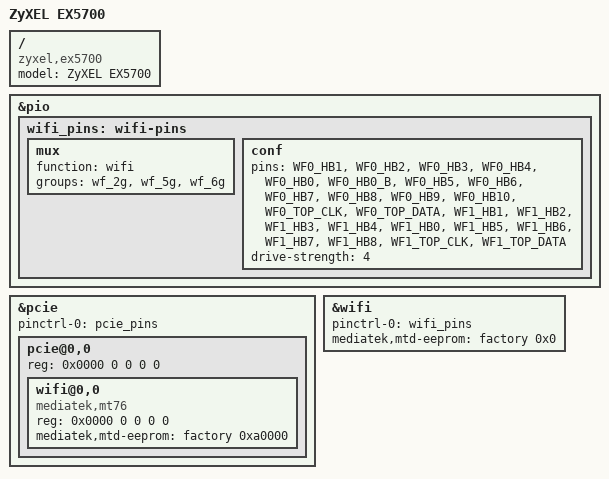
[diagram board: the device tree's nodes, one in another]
// SPDX-License-Identifier: (GPL-2.0 OR MIT)

/dts-v1/;

#include "mt7986a-zyxel-ex5700-common.dtsi"

/ {
	model = "ZyXEL EX5700";
	compatible = "zyxel,ex5700", "mediatek,mt7986a";
};

&pio {
	wifi_pins: wifi-pins {
		mux {
			function = "wifi";
			groups = "wf_2g", "wf_5g", "wf_6g";
		};
		conf {
			pins = "WF0_HB1", "WF0_HB2", "WF0_HB3", "WF0_HB4",
			       "WF0_HB0", "WF0_HB0_B", "WF0_HB5", "WF0_HB6",
			       "WF0_HB7", "WF0_HB8", "WF0_HB9", "WF0_HB10",
			       "WF0_TOP_CLK", "WF0_TOP_DATA", "WF1_HB1",
			       "WF1_HB2", "WF1_HB3", "WF1_HB4", "WF1_HB0",
			       "WF1_HB5", "WF1_HB6", "WF1_HB7", "WF1_HB8",
			       "WF1_TOP_CLK", "WF1_TOP_DATA";
			drive-strength = <4>;
		};
	};

};

&pcie {
	pinctrl-names = "default";
	pinctrl-0 = <&pcie_pins>;
	status = "okay";

	pcie@0,0 {
		reg = <0x0000 0 0 0 0>;

		wifi@0,0 {
			compatible = "mediatek,mt76";
			reg = <0x0000 0 0 0 0>;
			mediatek,mtd-eeprom = <&factory 0xa0000>;
		};
	};
};

&wifi {
	status = "okay";
	pinctrl-names = "default";
	pinctrl-0 = <&wifi_pins>;
	mediatek,mtd-eeprom = <&factory 0x0>;
};
